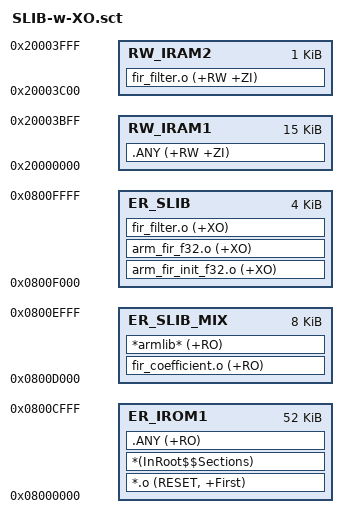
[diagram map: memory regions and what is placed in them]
; *************************************************************
; *** Scatter-Loading Description File generated by uVision ***
; *************************************************************

; This Scatter file is used for AT32F421C8T7 ( flash size is 64KB, page size is 1KB)

LR_IROM1 0x08000000 0x00010000  {    ; user code area
  ER_IROM1 0x08000000 0x0000D000  { 
    *.o (RESET, +First)
    *(InRoot$$Sections)
    .ANY (+RO)		
  }
  
  RW_IRAM1 0x20000000 0x00003C00  {  ; user RAM area
    .ANY (+RW +ZI)
  }
   
  RW_IRAM2 0x20003C00 0x00000400  {  ; RAM used for sLIB code
    fir_filter.o (+RW +ZI) 
  }   
}

LR_SLIB_READ_ONLY 0x0800D000 0x00002000  {        
  ER_SLIB_MIX 0x0800D000 0x00002000  { 
    fir_coefficient.o (+RO)              ; data for sLib code
	  *armlib* (+RO)                       ; C and sowtware floating point library
  }
}

LR_SLIB_CODE 0x0800F000 0x0001000  {      ; sLib code
  ER_SLIB 0x0800F000 0x00001000  {  
	  arm_fir_init_f32.o (+XO)
	  arm_fir_f32.o (+XO)
	  fir_filter.o (+XO)   
  }
  
}


 


